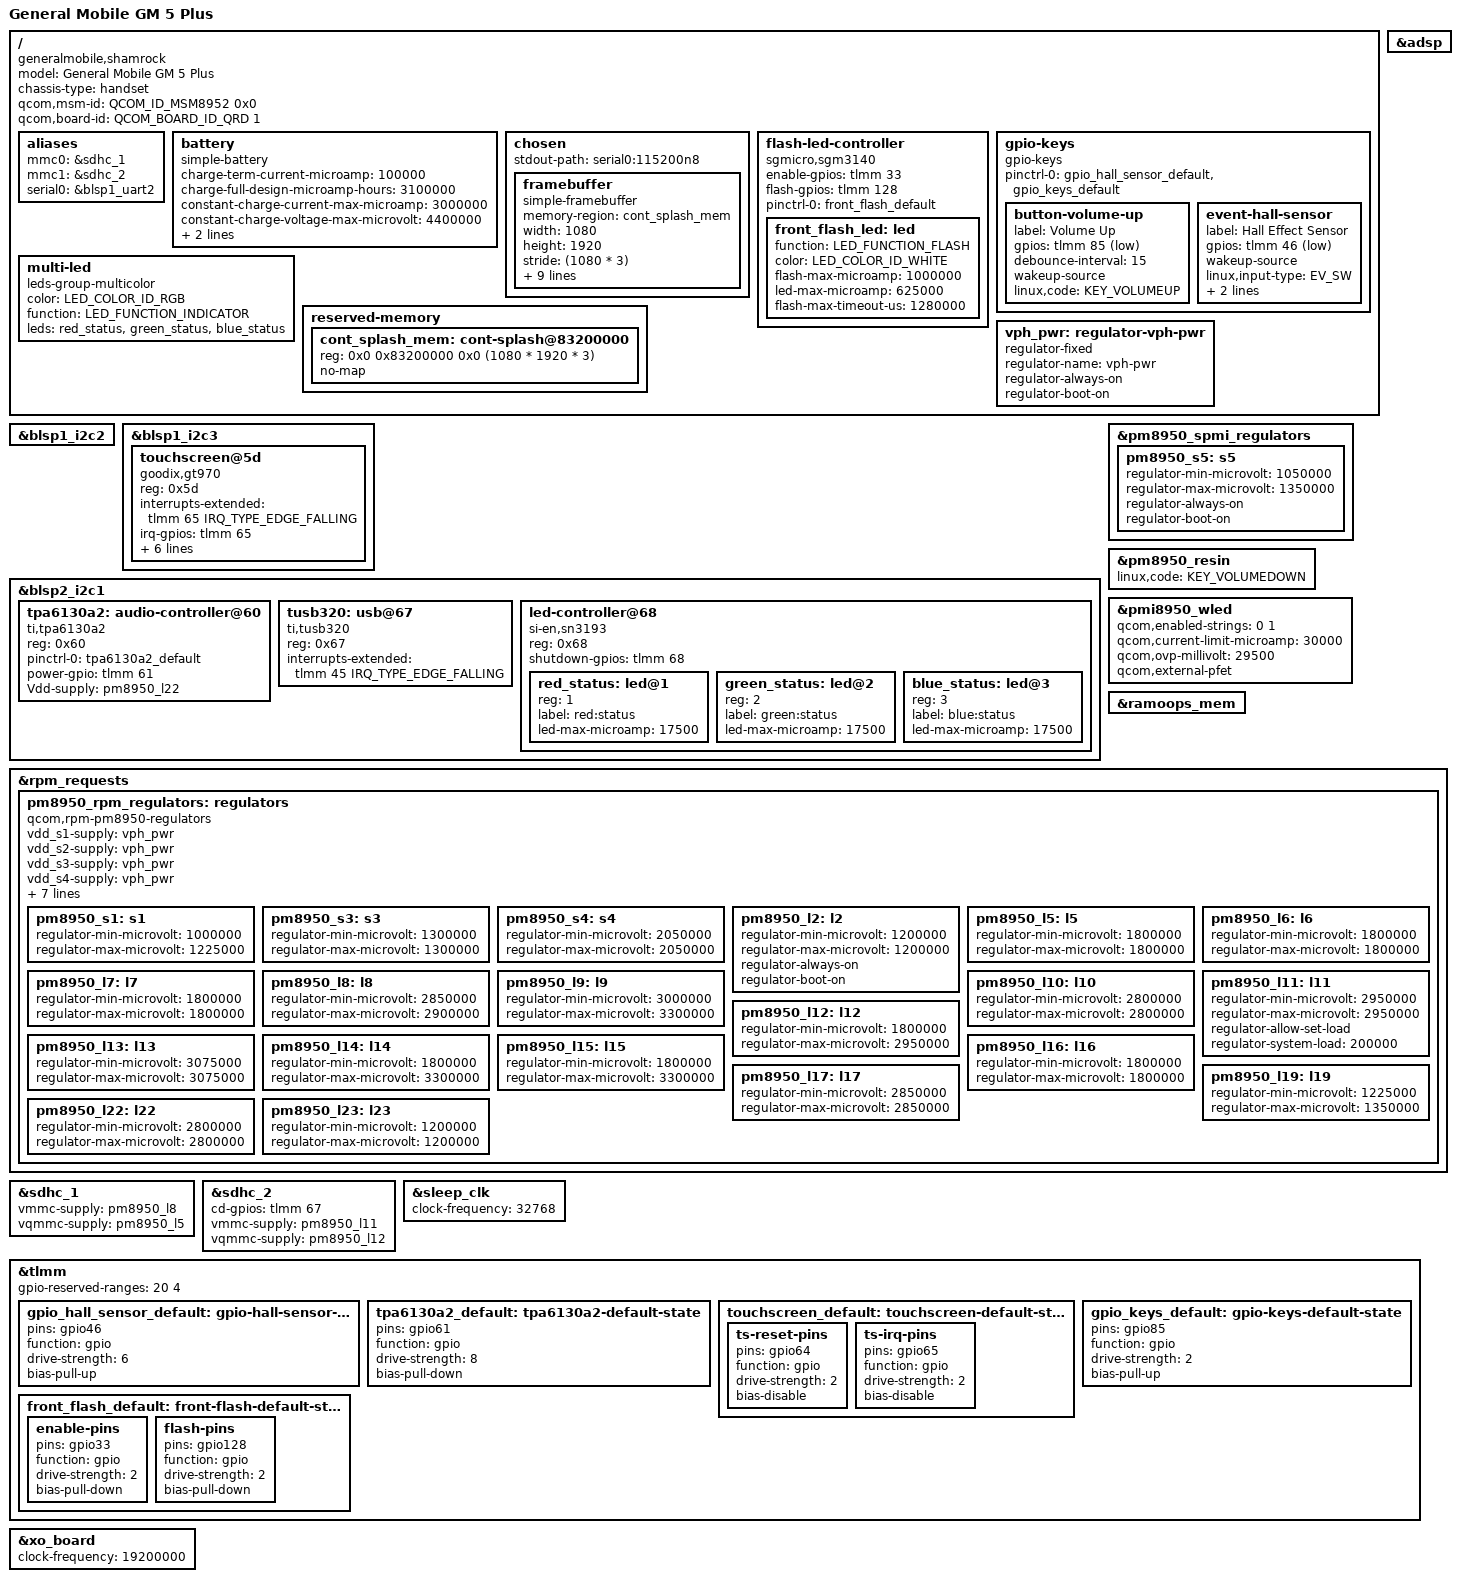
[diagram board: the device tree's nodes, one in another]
// SPDX-License-Identifier: GPL-2.0-only

/dts-v1/;

#include "msm8952.dtsi"
#include "pm8950.dtsi"
#include "pmi8950.dtsi"
#include <dt-bindings/gpio/gpio.h>
#include <dt-bindings/leds/common.h>

/ {
	model = "General Mobile GM 5 Plus";
	compatible = "generalmobile,shamrock", "qcom,msm8952";
	chassis-type = "handset";
	qcom,msm-id = <QCOM_ID_MSM8952 0x0>;
	qcom,board-id = <QCOM_BOARD_ID_QRD 1>;

	aliases {
		mmc0 = &sdhc_1; /* SDC1 eMMC slot */
		mmc1 = &sdhc_2; /* SDC2 SD card slot */
		serial0 = &blsp1_uart2;
	};

	battery: battery {
		compatible = "simple-battery";

		charge-term-current-microamp = <100000>;
		charge-full-design-microamp-hours = <3100000>;
		constant-charge-current-max-microamp = <3000000>;
		constant-charge-voltage-max-microvolt = <4400000>;
		voltage-min-design-microvolt = <3400000>;
		voltage-max-design-microvolt = <4400000>;
	};

	chosen {
		stdout-path = "serial0:115200n8";

		framebuffer {
			compatible = "simple-framebuffer";
			memory-region = <&cont_splash_mem>;

			width = <1080>;
			height = <1920>;
			stride = <(1080 * 3)>;
			format = "r8g8b8";

			power-domains = <&gcc MDSS_GDSC>;

			clocks = <&gcc GCC_MDSS_AHB_CLK>,
				 <&gcc GCC_MDSS_AXI_CLK>,
				 <&gcc GCC_MDSS_VSYNC_CLK>,
				 <&gcc GCC_MDSS_MDP_CLK>,
				 <&gcc GCC_MDSS_BYTE0_CLK>,
				 <&gcc GCC_MDSS_PCLK0_CLK>,
				 <&gcc GCC_MDSS_ESC0_CLK>;
		};
	};

	/* Front Flash */
	flash-led-controller {
		compatible = "sgmicro,sgm3140";

		enable-gpios = <&tlmm 33 GPIO_ACTIVE_HIGH>;
		flash-gpios = <&tlmm 128 GPIO_ACTIVE_HIGH>;

		pinctrl-0 = <&front_flash_default>;
		pinctrl-names = "default";

		front_flash_led: led {
			function = LED_FUNCTION_FLASH;
			color = <LED_COLOR_ID_WHITE>;
			flash-max-microamp = <1000000>;
			led-max-microamp = <625000>;
			flash-max-timeout-us = <1280000>;
		};
	};

	gpio-keys {
		compatible = "gpio-keys";

		pinctrl-0 = <&gpio_hall_sensor_default>, <&gpio_keys_default>;
		pinctrl-names = "default";

		button-volume-up {
			label = "Volume Up";
			gpios = <&tlmm 85 GPIO_ACTIVE_LOW>;
			debounce-interval = <15>;
			wakeup-source;
			linux,code = <KEY_VOLUMEUP>;
		};

		event-hall-sensor {
			label = "Hall Effect Sensor";
			gpios = <&tlmm 46 GPIO_ACTIVE_LOW>;
			wakeup-source;
			linux,input-type = <EV_SW>;
			linux,code = <SW_LID>;
			linux,can-disable;
		};
	};

	multi-led {
		compatible = "leds-group-multicolor";
		color = <LED_COLOR_ID_RGB>;
		function = LED_FUNCTION_INDICATOR;
		leds = <&red_status>, <&green_status>, <&blue_status>;
	};

	reserved-memory {
		cont_splash_mem: cont-splash@83200000 {
			reg = <0x0 0x83200000 0x0 (1080 * 1920 * 3)>;
			no-map;
		};
	};

	vph_pwr: regulator-vph-pwr {
		compatible = "regulator-fixed";
		regulator-name = "vph-pwr";
		regulator-always-on;
		regulator-boot-on;
	};
};

&adsp {
	status = "okay";
};

&blsp1_i2c2 {
	status = "okay";
	/* SMB1351 @1d charger */
	/* wsa881x-i2c @e @44 @f @45 audio amplifier */
};

&blsp1_i2c3 {
	status = "okay";

	/* himax,852x@48 Touchscreen */

	touchscreen@5d {
		compatible = "goodix,gt970", "goodix,gt911";
		reg = <0x5d>;
		interrupts-extended = <&tlmm 65 IRQ_TYPE_EDGE_FALLING>;
		irq-gpios = <&tlmm 65 GPIO_ACTIVE_HIGH>;
		reset-gpios = <&tlmm 64 GPIO_ACTIVE_HIGH>;
		AVDD28-supply = <&pm8950_l10>;
		VDDIO-supply = <&pm8950_l6>;

		pinctrl-0 = <&touchscreen_default>;
		pinctrl-names = "default";

		touchscreen-size-x = <1080>;
		touchscreen-size-y = <1920>;
	};
};

&blsp2_i2c1 {
	status = "okay";

	/* FUSB301 @25 USB-C Controller */

	tpa6130a2: audio-controller@60 {
		compatible = "ti,tpa6130a2";
		reg = <0x60>;
		pinctrl-0 = <&tpa6130a2_default>;
		pinctrl-names = "default";
		power-gpio = <&tlmm 61 GPIO_ACTIVE_HIGH>;
		Vdd-supply = <&pm8950_l22>;
	};

	tusb320: usb@67 {
		compatible = "ti,tusb320";
		reg = <0x67>;
		interrupts-extended = <&tlmm 45 IRQ_TYPE_EDGE_FALLING>;
	};

	led-controller@68 {
		compatible = "si-en,sn3193";
		reg = <0x68>;

		shutdown-gpios = <&tlmm 68 GPIO_ACTIVE_HIGH>;

		#address-cells = <1>;
		#size-cells = <0>;

		red_status: led@1 {
			reg = <1>;
			label = "red:status";
			led-max-microamp = <17500>;
		};

		green_status: led@2 {
			reg = <2>;
			label = "green:status";
			led-max-microamp = <17500>;
		};

		blue_status: led@3 {
			reg = <3>;
			label = "blue:status";
			led-max-microamp = <17500>;
		};
	};
};

&pm8950_spmi_regulators {
	/* PM8950 S5 + S6 = VDD_APC supply */
	pm8950_s5: s5 {
		regulator-min-microvolt = <1050000>;
		regulator-max-microvolt = <1350000>;
		regulator-always-on;
		regulator-boot-on;
	};
};

&pm8950_resin {
	linux,code = <KEY_VOLUMEDOWN>;

	status = "okay";
};

&pmi8950_wled {
	qcom,enabled-strings = <0 1>;
	qcom,current-limit-microamp = <30000>;
	qcom,ovp-millivolt = <29500>;
	qcom,external-pfet;

	status = "okay";
};

&ramoops_mem {
	status = "okay";
};

&rpm_requests {
	pm8950_rpm_regulators: regulators {
		compatible = "qcom,rpm-pm8950-regulators";
		vdd_s1-supply = <&vph_pwr>;
		vdd_s2-supply = <&vph_pwr>;
		vdd_s3-supply = <&vph_pwr>;
		vdd_s4-supply = <&vph_pwr>;
		vdd_s6-supply = <&vph_pwr>;
		vdd_l1_l19-supply = <&pm8950_s3>;
		vdd_l2_l23-supply = <&pm8950_s3>;
		vdd_l3-supply = <&pm8950_s3>;
		vdd_l5_l6_l7_l16-supply = <&pm8950_s4>;
		vdd_l8_l11_l12_l17_l22-supply = <&vph_pwr>;
		vdd_l9_l10_l13_l14_l15_l18-supply = <&vph_pwr>;

		pm8950_s1: s1 {
			regulator-min-microvolt = <1000000>;
			regulator-max-microvolt = <1225000>;
		};

		pm8950_s3: s3 {
			regulator-min-microvolt = <1300000>;
			regulator-max-microvolt = <1300000>;
		};

		pm8950_s4: s4 {
			regulator-min-microvolt = <2050000>;
			regulator-max-microvolt = <2050000>;
		};

		pm8950_l2: l2 {
			regulator-min-microvolt = <1200000>;
			regulator-max-microvolt = <1200000>;
			regulator-always-on;
			regulator-boot-on;
		};

		/* pm8950_l3 is managed by rpmpd (RPMPD_VDDMX) */

		pm8950_l5: l5 {
			regulator-min-microvolt = <1800000>;
			regulator-max-microvolt = <1800000>;
		};

		pm8950_l6: l6 {
			regulator-min-microvolt = <1800000>;
			regulator-max-microvolt = <1800000>;
		};

		pm8950_l7: l7 {
			regulator-min-microvolt = <1800000>;
			regulator-max-microvolt = <1800000>;
		};

		pm8950_l8: l8 {
			regulator-min-microvolt = <2850000>;
			regulator-max-microvolt = <2900000>;
		};

		pm8950_l9: l9 {
			regulator-min-microvolt = <3000000>;
			regulator-max-microvolt = <3300000>;
		};

		pm8950_l10: l10 {
			regulator-min-microvolt = <2800000>;
			regulator-max-microvolt = <2800000>;
		};

		pm8950_l11: l11 {
			regulator-min-microvolt = <2950000>;
			regulator-max-microvolt = <2950000>;
			regulator-allow-set-load;
			regulator-system-load = <200000>;
		};

		pm8950_l12: l12 {
			regulator-min-microvolt = <1800000>;
			regulator-max-microvolt = <2950000>;
		};

		pm8950_l13: l13 {
			regulator-min-microvolt = <3075000>;
			regulator-max-microvolt = <3075000>;
		};

		pm8950_l14: l14 {
			regulator-min-microvolt = <1800000>;
			regulator-max-microvolt = <3300000>;
		};

		pm8950_l15: l15 {
			regulator-min-microvolt = <1800000>;
			regulator-max-microvolt = <3300000>;
		};

		pm8950_l16: l16 {
			regulator-min-microvolt = <1800000>;
			regulator-max-microvolt = <1800000>;
		};

		pm8950_l17: l17 {
			regulator-min-microvolt = <2850000>;
			regulator-max-microvolt = <2850000>;
		};

		pm8950_l19: l19 {
			regulator-min-microvolt = <1225000>;
			regulator-max-microvolt = <1350000>;
		};

		pm8950_l22: l22 {
			regulator-min-microvolt = <2800000>;
			regulator-max-microvolt = <2800000>;
		};

		pm8950_l23: l23 {
			regulator-min-microvolt = <1200000>;
			regulator-max-microvolt = <1200000>;
		};
	};
};

&sdhc_1 {
	vmmc-supply = <&pm8950_l8>;
	vqmmc-supply = <&pm8950_l5>;

	status = "okay";
};

&sdhc_2 {
	cd-gpios = <&tlmm 67 GPIO_ACTIVE_HIGH>;
	vmmc-supply = <&pm8950_l11>;
	vqmmc-supply = <&pm8950_l12>;

	status = "okay";
};

&sleep_clk {
	clock-frequency = <32768>;
};

&tlmm {
	gpio-reserved-ranges = <20 4>; /* Unknown, TZ Protected */

	gpio_hall_sensor_default: gpio-hall-sensor-default-state {
		pins = "gpio46";
		function = "gpio";
		drive-strength = <6>;
		bias-pull-up;
	};

	tpa6130a2_default: tpa6130a2-default-state {
		pins = "gpio61";
		function = "gpio";
		drive-strength = <8>;
		bias-pull-down;
	};

	touchscreen_default: touchscreen-default-state {
		ts-reset-pins {
			pins = "gpio64";
			function = "gpio";
			drive-strength = <2>;
			bias-disable;
		};

		ts-irq-pins {
			pins = "gpio65";
			function = "gpio";
			drive-strength = <2>;
			bias-disable;
		};
	};

	gpio_keys_default: gpio-keys-default-state {
		pins = "gpio85";
		function = "gpio";
		drive-strength = <2>;
		bias-pull-up;
	};

	front_flash_default: front-flash-default-state {
		enable-pins {
			pins = "gpio33";
			function = "gpio";
			drive-strength = <2>;
			bias-pull-down;
		};

		flash-pins {
			pins = "gpio128";
			function = "gpio";
			drive-strength = <2>;
			bias-pull-down;
		};
	};
};

&xo_board {
	clock-frequency = <19200000>;
};
